# FM33L0XXD register map
File version: 1.0
CPU: SC000 r1p0, little endian, no MPU, FPU, 8 interrupt priority bits
Registers are 32-bit, read-write, reset 0x0 unless marked. A register's access mark holds for its fields unless they carry their own. Offsets are from the block's base; [hi:lo] are bit positions; {n}, {i} and the like mark numbered series.

## TRNG — TRNG module information
Base 0x40013C00
0x04 DOR
  [31:0] RNGOUT ro — RNGOUT field description
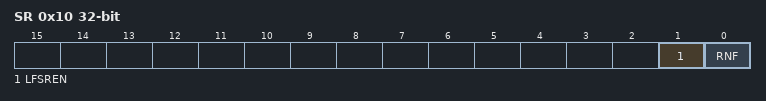
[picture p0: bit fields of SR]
0x10 SR
  [1] LFSREN ro — LFSREN field description
  [0] RNF — RNF field description
0x14 CRCCR
  [0] CRCEN — CRCEN field description
0x18 CRCDIR reset 0xFFFFFFFF
  [31:0] CRCIN — CRCIN field description
0x1C CRCSR
  [0] CRCDONE — CRCDONE field description

## TRNGCON — TRNGCON module information
Base 0x4001238C
0x00 CR
  [0] RNGEN — RNGEN field description

## U78160 — U78160 module information
Base 0x40011C00
Same registers: U78161 0x40011C2C
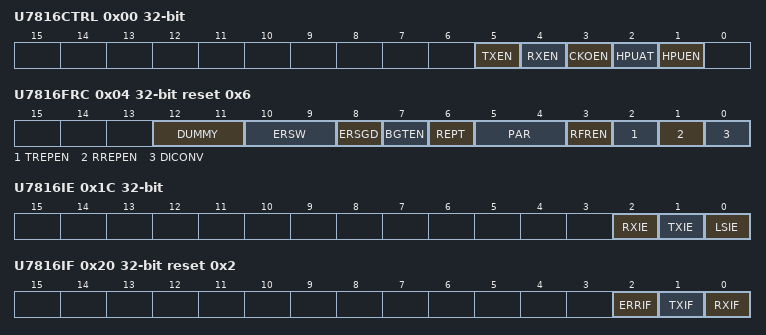
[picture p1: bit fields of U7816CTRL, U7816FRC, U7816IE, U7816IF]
0x00 U7816CTRL
  [5] TXEN — TXEN field description
  [4] RXEN — RXEN field description
  [3] CKOEN — CKOEN field description
  [2] HPUAT — HPUAT field description
  [1] HPUEN — HPUEN field description
0x04 U7816FRC reset 0x6
  [12:11] DUMMY ro — DUMMY field description
  [10:9] ERSW — ERSW field description
  [8] ERSGD — ERSGD field description
  [7] BGTEN — BGTEN field description
  [6] REPT — REP_T field description
  [5:4] PAR — PAR field description
  [3] RFREN — RFREN field description
  [2] TREPEN — TREPEN field description
  [1] RREPEN — RREPEN field description
  [0] DICONV — DICONV field description
0x08 U7816EGTC
  [7:0] TXEGT — TXEGT field description
0x0C U7816CLKDIV reset 0x3
  [4:0] CLKDIV — CLKDIV field description
0x10 U7816PDIV reset 0x173
  [11:0] PDIV — PDIV field description
0x14 U7816RXBUF
  [7:0] RXBUF ro — RXBUF field description
0x18 U7816TXBUF
  [7:0] TXBUF — TXBUF field description
0x1C U7816IE
  [2] RXIE — RXIE field description
  [1] TXIE — TXIE field description
  [0] LSIE — LSIE field description
0x20 U7816IF reset 0x2
  [2] ERRIF ro — ERRIF field description
  [1] TXIF ro — TXIF field description
  [0] RXIF ro — RXIF field description
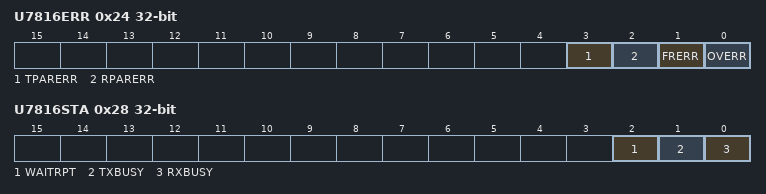
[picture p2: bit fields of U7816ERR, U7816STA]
0x24 U7816ERR
  [3] TPARERR — TPARERR field description
  [2] RPARERR — RPARERR field description
  [1] FRERR — FRERR field description
  [0] OVERR — OVERR field description
0x28 U7816STA
  [2] WAITRPT ro — WAIT_RPT field description
  [1] TXBUSY ro — TXBUSY field description
  [0] RXBUSY ro — RXBUSY field description

## UART0 — UART0 module information
Base 0x4001200C
Same registers: UART1 0x4001202C, UART2 0x4001204C, UART3 0x4001206C, UART4 0x4001208C, UART5 0x400120AC
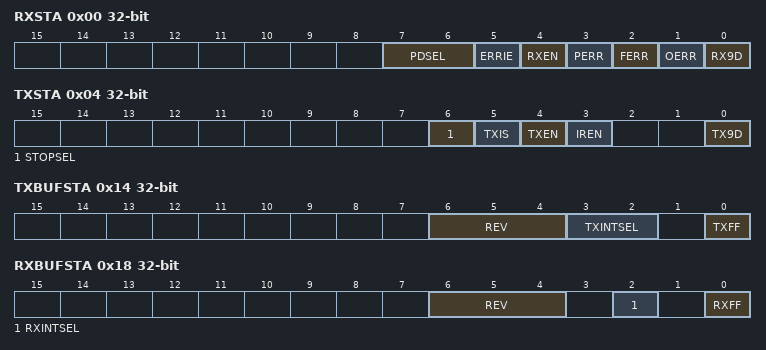
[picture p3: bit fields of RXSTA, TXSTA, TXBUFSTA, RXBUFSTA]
0x00 RXSTA
  [7:6] PDSEL — PDSEL field description
  [5] ERRIE — ERRIE field description
  [4] RXEN — RXEN field description
  [3] PERR — PERR field description
  [2] FERR — FERR field description
  [1] OERR — OERR field description
  [0] RX9D ro — RX9D field description
0x04 TXSTA
  [6] STOPSEL — STOPSEL field description
  [5] TXIS — TXIS field description
  [4] TXEN — TXEN field description
  [3] IREN — IREN field description
  [0] TX9D ro — TX9D field description
0x08 RXREG
  [7:0] RXREG ro — RXREG field description
0x0C TXREG
  [7:0] TXREG wo — TXREG field description
0x10 SPBRG reset 0x41
  [15:0] SPBRG — SPBRG field description
0x14 TXBUFSTA
  [6:4] REV — REV field description
  [3:2] TXINTSEL — TX_INTSEL field description
  [0] TXFF ro — TXFF field description
0x18 RXBUFSTA
  [6:4] REV — REV field description
  [2] RXINTSEL — RX_INTSEL field description
  [0] RXFF ro — RXFF field description
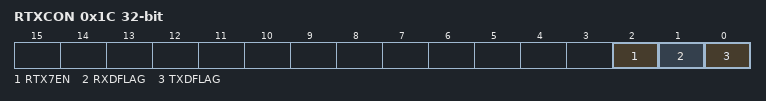
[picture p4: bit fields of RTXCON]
0x1C RTXCON
  [2] RTX7EN — RTX7EN field description
  [1] RXDFLAG — RXDFLAG field description
  [0] TXDFLAG — TXDFLAG field description

## UARTCOM — UARTCOM module information
Base 0x40012000
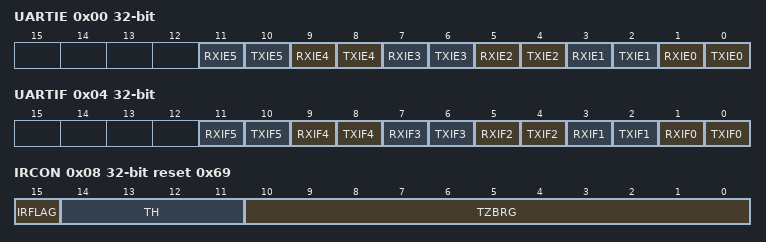
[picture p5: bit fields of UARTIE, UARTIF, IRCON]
0x00 UARTIE
  [2n+1] RXIE{n} (n=0..5) — RXIE{n} field description
  [2n] TXIE{n} (n=0..5) — TXIE{n} field description
0x04 UARTIF
  [2n+1] RXIF{n} (n=0..5) — RXIF{n} field description
  [2n] TXIF{n} (n=0..5) — TXIF{n} field description
0x08 IRCON reset 0x69
  [15] IRFLAG — IRFLAG field description
  [14:11] TH — TH field description
  [10:0] TZBRG — TZBRG field description

## WWDT — WWDT module information
Base 0x40011800
0x00 WWDTCON
  [9:0] WWDTCON wo — WWDTCON field description
0x04 WWDTCFG
  [2:0] CFG ro — WWDT_CFG field description
0x08 WWDTCNT
  [9:0] CNT ro — WWDT_CNT field description
0x0C WWDTIE
  [0] IE — WWDT_IE field description
0x10 WWDTIF
  [0] WARNIF — WWDT_WARN_IF field description
0x14 WWDTDIV
  [11:0] DIVCNT ro — DIV_CNT field description
